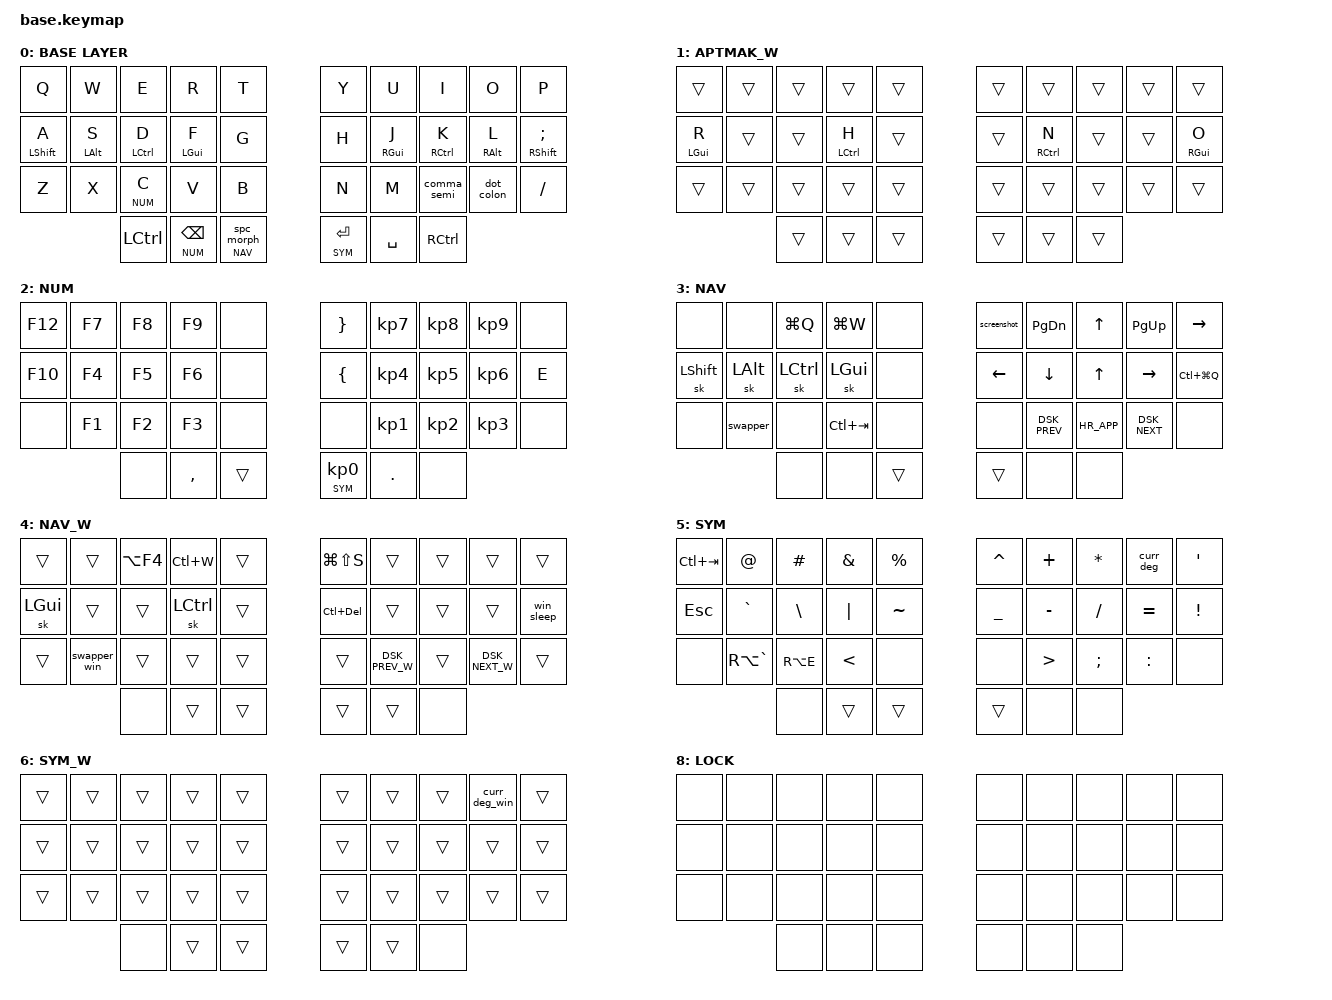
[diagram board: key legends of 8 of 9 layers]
#include <behaviors.dtsi>
#include <dt-bindings/zmk/keys.h>
#include <dt-bindings/zmk/outputs.h>


// layers ID definition
#define BASE 0
#define BASE_WIN 1
#define NUM 2
#define NAV 3
#define NAVW 4
#define SYM 5
#define SYMW 6
#define ADJ 7
#define LOCKL 8

#define xxx &none
#define ___ &trans

#include "combos.dtsi"
#include "extra_keys.h"
#if WIRELESS
    #include <dt-bindings/zmk/bt.h>
    #define BTL1  &bt BT_CLR   &bt BT_SEL 2  &pc_connect   &osx_connect
    #define BTL2  xxx          &bt BT_SEL 4  &bt BT_SEL 3  &out OUT_TOG
#else
    #define BTL1  xxx   xxx   xxx   xxx
    #define BTL2  xxx   xxx   xxx   xxx
#endif

// tapping term definition
#define TAP_TERM_MS 200
#define QUICK_TAP_MS 125

// macros definition
#define meh LG(LC(LALT))
#define hyper LG(LC(LS(LALT)))
#define deg RA(LS(N8))
#define HR_APP LG(LS(SPACE))
#define DSK_PREV_W LG(LC(LEFT))
#define DSK_NEXT_W LG(LC(RIGHT))

// OSX specific macros
#define undo LG(Z)
#define redo LG(LS(Z))
#define DSK_PREV LC(LEFT)
#define DSK_NEXT LC(RIGHT)
#define prev_win LG(TAB)
#define next_win LG(LS(TAB))

// 36 keys physical layout
#define LEFT_KEYS 0 1 2 3 4 10 11 12 13 14 20 21 22 23 24 // left-hand keys
#define RIGHT_KEYS 5 6 7 8 9 15 16 17 18 19 25 26 27 28 29 // right-hand keys
#define THUMBS 30 31 32 33 34 35 // thumb keys

// tune mod tap
&mt {
    flavor = "tap-preferred";
    tapping_term_ms = <200>;
};

// layer tap config
&lt {
    flavor = "balanced";
    tapping-term-ms = <TAP_TERM_MS>;
    quick-tap-ms = <QUICK_TAP_MS>;      // double-tap + hold repeats tap-key
};

// tune sticky key
&sk {
    release-after-ms = <1000>;
    quick-release;
};

// sticky layer config
&sl {
    release-after-ms = <700>;
};

// caps word settings
&caps_word {
    continue-list = <UNDERSCORE MINUS BSPC N1 N2 N3 N4 N5 N6 N7 N8 N9 N0>;
};


// main tree
/ {
    behaviors {
        // HOME ROW MODS
        hml: left_hand_positional_hold_tap {
            compatible = "zmk,behavior-hold-tap";
            label = "LEFT_POSITIONAL_HOLD_TAP";
            #binding-cells = <2>;
            flavor = "balanced";
            tapping-term-ms = <TAP_TERM_MS>;
            quick-tap-ms = <QUICK_TAP_MS>;       // double-tap + hold repeats tap-key
            require-prior-idle-ms = <100>;       // do not activate HOLD during typing flow
            bindings = <&kp>, <&kp>;
            hold-trigger-key-positions = <RIGHT_KEYS THUMBS>;
            hold-trigger-on-release;
        };

        hmr: right_hand_positional_hold_tap {
            compatible = "zmk,behavior-hold-tap";
            label = "RIGHT_POSITIONAL_HOLD_TAP";
            #binding-cells = <2>;
            flavor = "balanced";
            tapping-term-ms = <TAP_TERM_MS>;
            quick-tap-ms = <QUICK_TAP_MS>;       // double-tap + hold repeats tap-key
            require-prior-idle-ms = <100>;       // do not activate HOLD during typing flow
            bindings = <&kp>, <&kp>;
            hold-trigger-key-positions = <LEFT_KEYS THUMBS>;
            hold-trigger-on-release;
        };

        // TAP DANCES
        curr_deg: tap_dance_curr_deg {
            compatible = "zmk,behavior-tap-dance";
            label = "TAP_DANCE_curr_deg";
            #binding-cells = <0>;
            tapping-term-ms = <TAP_TERM_MS>;
            bindings = <&kp DLLR>, <&kp LA(N5)>, <&kp deg>;
        };
        curr_deg_win: tap_dance_curr_deg_win {
            compatible = "zmk,behavior-tap-dance";
            label = "TAP_DANCE_curr_deg_win";
            #binding-cells = <0>;
            tapping-term-ms = <TAP_TERM_MS>;
            bindings = <&kp DLLR>, <&macro_euro_win>, <&macro_deg_win>;
        };
        prev_next_song: prev_next_song {
            compatible = "zmk,behavior-tap-dance";
            label = "PREV_NEXT_SONG";
            #binding-cells = <0>;
            tapping-term-ms = <TAP_TERM_MS>;
            bindings = <&kp C_NEXT>, <&kp C_PREV>;
        };
        screenshot: screenshot { // single-tap: area selector, double-tap: full-screen
            compatible = "zmk,behavior-tap-dance";
            label = "SCREENSHOT";
            #binding-cells = <0>;
            tapping-term-ms = <TAP_TERM_MS>;
            bindings = <&kp LG(LS(NUMBER_4))>, <&kp LG(LS(NUMBER_3))>;
        };

        // tap: sticky-shift | lshft + tap: caps-word | hold: set in keymap (HYPER)
        ss_cw: ss_cw {
            compatible = "zmk,behavior-mod-morph";
            label = "SS_CW";
            #binding-cells = <0>;
            bindings = <&sk LSHFT>, <&caps_word>;
            mods = <(MOD_LSFT|MOD_RSFT)>;
        };
        lt_shft: lt_shft {
            compatible = "zmk,behavior-hold-tap";
            label = "LT_SHFT";
            #binding-cells = <2>;
            tapping-term-ms = <TAP_TERM_MS>;
            quick-tap-ms = <QUICK_TAP_MS>;
            flavor = "balanced";
            bindings = <&kp>, <&ss_cw>;
        };

        // tap: space | shft + tap: dot -> space -> sticky shift | hold: activate layer
        spc_morph: spc_morph {
            compatible = "zmk,behavior-mod-morph";
            label = "SPC_MORPH";
            #binding-cells = <0>;
            bindings = <&kp SPACE>, <&dot_spc>;
            mods = <(MOD_LSFT)>;
        };
        lt_spc: lt_spc {
            compatible = "zmk,behavior-hold-tap";
            label = "LT_SPC";
            #binding-cells = <2>;
            tapping-term-ms = <TAP_TERM_MS>;
            quick-tap-ms = <QUICK_TAP_MS>;
            flavor = "balanced";
            bindings = <&mo>, <&spc_morph>;
        };

        // Alt+Tab swapper, requires PR #1366
        swapper: swapper{
            compatible = "zmk,behavior-tri-state";
            label = "SWAPPER";
            #binding-cells = <0>;
            bindings = <&kt LGUI>, <&kp TAB>, <&kt LGUI>;
            ignored-key-positions = <31>; // the key being held for the layer activation
        };

        swapper_win: swapper_win{
            compatible = "zmk,behavior-tri-state";
            label = "SWAPPER";
            #binding-cells = <0>;
            bindings = <&kt LCTRL>, <&kp TAB>, <&kt LCTRL>;
            ignored-key-positions = <31>; // the key being held for the layer activation
        };

        //usefull mod-morphs
        dot_colon: dot_colon {
            compatible = "zmk,behavior-mod-morph";
            label = "DOT_TO_COLON";
            #binding-cells = <0>;
            bindings = <&kp DOT>, <&kp COLON>;
            mods = <(MOD_LSFT|MOD_RSFT)>;
        };
        comma_semi: comma_semi {
            compatible = "zmk,behavior-mod-morph";
            label = "COMMA_TO_SEMICOLON";
            #binding-cells = <0>;
            bindings = <&kp COMMA>, <&kp SEMICOLON>;
            mods = <(MOD_LSFT|MOD_RSFT)>;
        };
        quest_excl: quest_excl {
            compatible = "zmk,behavior-mod-morph";
            label = "quest_to_excl";
            #binding-cells = <0>;
            bindings = <&kp QUESTION>, <&kp EXCLAMATION>;
            mods = <(MOD_LSFT|MOD_RSFT)>;
        };
        single_to_doublequote: single_to_doublequote {
            compatible = "zmk,behavior-mod-morph";
            label = "SINGLE_TO_DOUBLEQUOTE";
            #binding-cells = <0>;
            bindings = <&kp SINGLE_QUOTE>, <&kp DOUBLE_QUOTES>;
            mods = <(MOD_LSFT|MOD_RSFT)>;
        };
    };

    // macros
    macros {
        sel_word: select_word {
            label = "ZM_SELECT_WORD";
            compatible = "zmk,behavior-macro";
            #binding-cells = <0>;
            bindings
                = <&macro_press &kp LCTRL>
                , <&macro_tap &kp LEFT>
                , <&macro_press &kp LSHFT>
                , <&macro_tap &kp RIGHT>
                , <&macro_release &kp LSHFT &kp LCTRL>
                ;
        };

        del_line: del_line {
            label = "ZMK_DEL_LINE";
            compatible = "zmk,behavior-macro";
            #binding-cells = <0>;
            bindings
                = <&macro_press &kp END>
                , <&macro_press &kp LGUI>
                , <&macro_tap &kp HOME>
                , <&macro_release &kp LGUI>
                , <&macro_tap &kp BSPC>
                ;
        };

        del_line_win: del_line_win {
            label = "ZMK_DEL_LINE_WIN";
            compatible = "zmk,behavior-macro";
            #binding-cells = <0>;
            bindings
                = <&macro_press &kp END>
                , <&macro_press &kp LSHFT>
                , <&macro_tap &kp HOME>
                , <&macro_release &kp LSHFT>
                , <&macro_tap &kp BSPC>
                ;
        };

        dot_spc: dot_spc{
            label = "ZM_DOT_SPACE";
            compatible = "zmk,behavior-macro";
            #binding-cells = <0>;
            wait-ms = <0>;
            tap-ms = <5>;
            bindings = <&kp DOT &kp SPACE &sk LSHFT>;
        };

        // Windows sleep key (fix LOCK not working on Windows)
        win_sleep: win_sleep{
            label = "ZM_WIN_SLEEP";
            compatible = "zmk,behavior-macro";
            #binding-cells = <0>;
            wait-ms = <100>;
            tap-ms = <5>;
            bindings = <&kp LG(X) &kp U &kp S>;
        };

        #if WIRELESS
        pc_connect: pc_connect{
            label = "ZM_PC_CONNECT";
            compatible = "zmk,behavior-macro";
            #binding-cells = <0>;
            wait-ms = <100>;
            tap-ms = <5>;
            bindings = <&bt BT_SEL 1 &to BASE>;
        };
        osx_connect: osx_connect{
            label = "ZM_PC_CONNECT";
            compatible = "zmk,behavior-macro";
            #binding-cells = <0>;
            wait-ms = <100>;
            tap-ms = <5>;
            bindings = <&bt BT_SEL 0 &to BASE>;
        };
        #endif

        macro_par: macro_par{
            label = "ZM_PAR";
            compatible = "zmk,behavior-macro";
            #binding-cells = <0>;
            wait-ms = <0>;
            tap-ms = <5>;
            bindings = <&kp LPAR &kp RPAR &kp LEFT>;
        };
        macro_bkt: macro_bkt{
            label = "ZM_BKT";
            compatible = "zmk,behavior-macro";
            #binding-cells = <0>;
            wait-ms = <0>;
            tap-ms = <5>;
            bindings = <&kp LBKT &kp RBKT &kp LEFT>;
        };
        macro_brc: macro_brc{
            label = "ZM_BRC";
            compatible = "zmk,behavior-macro";
            #binding-cells = <0>;
            wait-ms = <0>;
            tap-ms = <5>;
            bindings = <&kp LBRC &kp RBRC &kp LEFT>;
        };
        macro_deg_win: macro_deg_win{
            label = "ZM_DEG";
            compatible = "zmk,behavior-macro";
            #binding-cells = <0>;
            wait-ms = <0>;
            tap-ms = <5>;
            bindings
                = <&macro_press   &kp LALT>
                , <&macro_tap     &kp KP_N0 &kp KP_N1 &kp KP_N7 &kp KP_N6>
                , <&macro_release &kp LALT>
                ;
        };
        macro_euro_win: macro_euro_win{
            label = "ZM_EURO";
            compatible = "zmk,behavior-macro";
            #binding-cells = <0>;
            wait-ms = <0>;
            tap-ms = <5>;
            bindings
                = <&macro_press   &kp LALT>
                , <&macro_tap     &kp KP_N0 &kp KP_N1 &kp KP_N2 &kp KP_N8>
                , <&macro_release &kp LALT>
                ;
        };
    };

    conditional_layers {
        compatible = "zmk,conditional-layers";
        tri_layer {
            if-layers = <NAV SYM>;
            then-layer = <ADJ>;
        };
        tri_layer_adj {
            if-layers = <NAVW SYMW>;
            then-layer = <ADJ>;
        };
        tri_layer_sym {
            if-layers = <BASE_WIN SYM>;
            then-layer = <SYMW>;
        };
        tri_layer_nav {
            if-layers = <BASE_WIN NAV>;
            then-layer = <NAVW>;
        };
    };

    keymap {
        compatible = "zmk,keymap";

        default_layer {
            label = "BASE LAYER";
            bindings = <
             //╭──────────────┬──────────────┬──────────────┬──────────────┬──────────────╮     ╭──────────────┬──────────────┬──────────────┬──────────────┬──────────────╮
                &kp Q            &kp W          &kp E          &kp R         &kp T                 &kp Y          &kp U          &kp I          &kp O          &kp P
             //├──────────────┼──────────────┼──────────────┼──────────────┼──────────────┤     ├──────────────┼──────────────┼──────────────┼──────────────┼──────────────┤
                &hml LSHIFT A   &hml LALT S    &hml LCTRL D  &hml LGUI F     &kp G                 &kp H          &hmr RGUI J    &hmr RCTRL K  &hmr RALT L  &hmr RSHIFT SEMI
             //├──────────────┼──────────────┼──────────────┼──────────────┼──────────────┤     ├──────────────┼──────────────┼──────────────┼──────────────┼──────────────┤
                &kp Z            &kp X          &lt NUM C      &kp V          &kp B                &kp N            &kp M        &comma_semi    &dot_colon     &kp SLASH
             //╰──────────────┴──────────────┼──────────────┼──────────────┼──────────────┤     ├──────────────┼──────────────┼──────────────┼──────────────┴──────────────╯
                                              &kp LCTRL        &lt NUM BSPC   &lt_spc NAV 0        &lt SYM RET      &kp SPACE      &kp RCTRL
             //                              ╰──────────────┴──────────────┴──────────────╯     ╰──────────────┴──────────────┴──────────────╯
            >;
        };

        default_win {
            label = "APTMAK_W";
            bindings = <
             //╭──────────────┬──────────────┬──────────────┬──────────────┬──────────────╮     ╭──────────────┬──────────────┬──────────────┬──────────────┬──────────────╮
                ___            ___            ___            ___            ___                  ___            ___            ___            ___            ___
             //├──────────────┼──────────────┼──────────────┼──────────────┼──────────────┤     ├──────────────┼──────────────┼──────────────┼──────────────┼──────────────┤
                &hml LGUI R    ___            ___            &hml LCTRL H   ___                  ___            &hmr RCTRL N   ___            ___            &hmr RGUI O
             //├──────────────┼──────────────┼──────────────┼──────────────┼──────────────┤     ├──────────────┼──────────────┼──────────────┼──────────────┼──────────────┤
                ___            ___            ___            ___            ___                  ___            ___            ___            ___            ___
             //╰──────────────┴──────────────┼──────────────┼──────────────┼──────────────┤     ├──────────────┼──────────────┼──────────────┼──────────────┴──────────────╯
                                              ___            ___            ___                  ___            ___            ___
             //                              ╰──────────────┴──────────────┴──────────────╯     ╰──────────────┴──────────────┴──────────────╯
            >;
        };

        num_layer{
            label = "NUM";
            bindings = <
             //╭──────────────┬──────────────┬──────────────┬──────────────┬──────────────╮     ╭──────────────┬──────────────┬──────────────┬──────────────┬──────────────╮
                &kp F12        &kp F7         &kp F8         &kp F9         xxx                  &kp RBRC       &kp KP_N7      &kp KP_N8      &kp KP_N9      xxx
             //├──────────────┼──────────────┼──────────────┼──────────────┼──────────────┤     ├──────────────┼──────────────┼──────────────┼──────────────┼──────────────┤
                &kp F10        &kp F4         &kp F5         &kp F6         xxx                  &kp LBRC       &kp KP_N4      &kp KP_N5      &kp KP_N6      &kp E
             //├──────────────┼──────────────┼──────────────┼──────────────┼──────────────┤     ├──────────────┼──────────────┼──────────────┼──────────────┼──────────────┤
                xxx            &kp F1         &kp F2         &kp F3         xxx                  xxx            &kp KP_N1      &kp KP_N2      &kp KP_N3      xxx
             //╰──────────────┴──────────────┼──────────────┼──────────────┼──────────────┤     ├──────────────┼──────────────┼──────────────┼──────────────┴──────────────╯
                                              xxx            &kp COMMA      ___                  &lt SYM KP_N0  &kp DOT        xxx
             //                              ╰──────────────┴──────────────┴──────────────╯     ╰──────────────┴──────────────┴──────────────╯
            >;
        };

        nav_layer{
            label = "NAV";
            bindings = <
             //╭──────────────┬──────────────┬──────────────┬──────────────┬──────────────╮     ╭──────────────┬──────────────┬──────────────┬──────────────┬──────────────╮
                xxx            xxx            &kp LG(Q)      &kp LG(W)      xxx                  &screenshot      &kp PG_DN      &kp UP         &kp PG_UP      &kp RIGHT
             //├──────────────┼──────────────┼──────────────┼──────────────┼──────────────┤     ├──────────────┼──────────────┼──────────────┼──────────────┼──────────────┤
                &sk LSHFT      &sk LALT       &sk LCTRL      &sk LGUI       xxx                  &kp LEFT         &kp DOWN        &kp UP       &kp RIGHT      &kp LC(LG(Q))
             //├──────────────┼──────────────┼──────────────┼──────────────┼──────────────┤     ├──────────────┼──────────────┼──────────────┼──────────────┼──────────────┤
                xxx            &swapper       xxx            &kp LC(TAB)    xxx                  xxx              &kp DSK_PREV   &kp HR_APP     &kp DSK_NEXT   xxx
             //╰──────────────┴──────────────┼──────────────┼──────────────┼──────────────┤     ├──────────────┼──────────────┼──────────────┼──────────────┴──────────────╯
                                              xxx            xxx            ___                  ___            xxx            xxx
             //                              ╰──────────────┴──────────────┴──────────────╯     ╰──────────────┴──────────────┴──────────────╯
            >;
        };

        nav_win{
            label = "NAV_W";
            bindings = <
             //╭──────────────┬──────────────┬──────────────┬──────────────┬──────────────╮     ╭──────────────┬──────────────┬──────────────┬──────────────┬──────────────╮
                ___            ___            &kp LA(F4)     &kp LC(W)      ___                  &kp LG(LS(S))  ___            ___            ___            ___
             //├──────────────┼──────────────┼──────────────┼──────────────┼──────────────┤     ├──────────────┼──────────────┼──────────────┼──────────────┼──────────────┤
                &sk LGUI       ___            ___            &sk LCTRL      ___                  &kp LC(DEL)    ___            ___            ___            &win_sleep
             //├──────────────┼──────────────┼──────────────┼──────────────┼──────────────┤     ├──────────────┼──────────────┼──────────────┼──────────────┼──────────────┤
                ___            &swapper_win   ___            ___            ___                  ___            &kp DSK_PREV_W ___            &kp DSK_NEXT_W ___
             //╰──────────────┴──────────────┼──────────────┼──────────────┼──────────────┤     ├──────────────┼──────────────┼──────────────┼──────────────┴──────────────╯
                                              xxx            ___            ___                  ___            ___            xxx
             //                              ╰──────────────┴──────────────┴──────────────╯     ╰──────────────┴──────────────┴──────────────╯
            >;
        };

        symbols {
            label = "SYM";
            bindings = <
             //╭──────────────┬──────────────┬──────────────┬──────────────┬──────────────╮     ╭──────────────┬──────────────┬──────────────┬──────────────┬──────────────╮
                &kp LC(TAB)       &kp AT         &kp HASH       &kp AMPS       &kp PERCENT          &kp CARET      &kp PLUS       &kp ASTRK      &curr_deg      &kp SQT
             //├──────────────┼──────────────┼──────────────┼──────────────┼──────────────┤     ├──────────────┼──────────────┼──────────────┼──────────────┼──────────────┤
                &kp ESCAPE        &kp GRAVE      &kp BSLH       &kp PIPE       &kp TILDE            &kp UNDER      &kp MINUS      &kp SLASH      &kp EQUAL      &kp EXCL
             //├──────────────┼──────────────┼──────────────┼──────────────┼──────────────┤     ├──────────────┼──────────────┼──────────────┼──────────────┼──────────────┤
                xxx            &kp RA(GRAVE)  &kp RA(E)      &kp LT         xxx                  xxx            &kp GT         &kp SEMI       &kp COLON      xxx
             //╰──────────────┴──────────────┼──────────────┼──────────────┼──────────────┤     ├──────────────┼──────────────┼──────────────┼──────────────┴──────────────╯
                                              xxx            ___            ___                  ___            xxx            xxx
             //                              ╰──────────────┴──────────────┴──────────────╯     ╰──────────────┴──────────────┴──────────────╯
            >;
        };

        symbols_win {
            label = "SYM_W";
            bindings = <
             //╭──────────────┬──────────────┬──────────────┬──────────────┬──────────────╮     ╭──────────────┬──────────────┬──────────────┬──────────────┬──────────────╮
                ___            ___            ___            ___            ___                  ___            ___            ___            &curr_deg_win  ___
             //├──────────────┼──────────────┼──────────────┼──────────────┼──────────────┤     ├──────────────┼──────────────┼──────────────┼──────────────┼──────────────┤
                ___            ___            ___            ___            ___                  ___            ___            ___            ___            ___
             //├──────────────┼──────────────┼──────────────┼──────────────┼──────────────┤     ├──────────────┼──────────────┼──────────────┼──────────────┼──────────────┤
                ___            ___            ___            ___            ___                  ___            ___            ___            ___            ___
             //╰──────────────┴──────────────┼──────────────┼──────────────┼──────────────┤     ├──────────────┼──────────────┼──────────────┼──────────────┴──────────────╯
                                              xxx            ___            ___                  ___            ___            xxx
             //                              ╰──────────────┴──────────────┴──────────────╯     ╰──────────────┴──────────────┴──────────────╯
            >;
        };

        adj_layer {
            label = "ADJ";
            bindings = <
             //╭──────────────┬──────────────┬──────────────┬──────────────┬──────────────╮     ╭──────────────┬──────────────┬──────────────┬──────────────┬──────────────╮
                &kp A            xxx            &to BASE_WIN   &to BASE       &bootloader          &bootloader    &kp C_PP       &kp C_NEXT     &kp C_PREV     xxx
             //├──────────────┼──────────────┼──────────────┼──────────────┼──────────────┤     ├──────────────┼──────────────┼──────────────┼──────────────┼──────────────┤
                BTL1                                                        &sys_reset           &sys_reset     &kp C_VOL_DN   &kp C_VOL_UP   &kp C_MUTE     xxx
             //├──────────────┼──────────────┼──────────────┼──────────────┼──────────────┤     ├──────────────┼──────────────┼──────────────┼──────────────┼──────────────┤
                BTL2                                                        xxx                  xxx            &kp C_BRI_DN   &kp C_BRI_UP   xxx            xxx
             //╰──────────────┴──────────────┼──────────────┼──────────────┼──────────────┤     ├──────────────┼──────────────┼──────────────┼──────────────┴──────────────╯
                                              xxx            xxx            xxx                  xxx            xxx            xxx
             //                              ╰──────────────┴──────────────┴──────────────╯     ╰──────────────┴──────────────┴──────────────╯
            >;
        };

        lock_layer {
            label = "LOCK";
            bindings = <
             //╭──────────────┬──────────────┬──────────────┬──────────────┬──────────────╮     ╭──────────────┬──────────────┬──────────────┬──────────────┬──────────────╮
                xxx            xxx            xxx            xxx            xxx                  xxx            xxx            xxx            xxx            xxx
             //├──────────────┼──────────────┼──────────────┼──────────────┼──────────────┤     ├──────────────┼──────────────┼──────────────┼──────────────┼──────────────┤
                xxx            xxx            xxx            xxx            xxx                  xxx            xxx            xxx            xxx            xxx
             //├──────────────┼──────────────┼──────────────┼──────────────┼──────────────┤     ├──────────────┼──────────────┼──────────────┼──────────────┼──────────────┤
                xxx            xxx            xxx            xxx            xxx                  xxx            xxx            xxx            xxx            xxx
             //╰──────────────┴──────────────┼──────────────┼──────────────┼──────────────┤     ├──────────────┼──────────────┼──────────────┼──────────────┴──────────────╯
                                              xxx            xxx            xxx                  xxx            xxx            xxx
             //                              ╰──────────────┴──────────────┴──────────────╯     ╰──────────────┴──────────────┴──────────────╯
            >;
        };

    };
};
